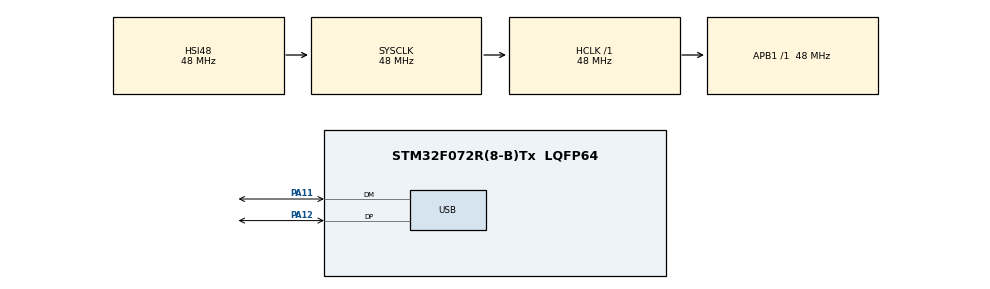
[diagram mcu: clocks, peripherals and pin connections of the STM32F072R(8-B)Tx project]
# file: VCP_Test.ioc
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Mcu.Family=STM32F0
Mcu.Name=STM32F072R(8-B)Tx
Mcu.Package=LQFP64
NVIC.USB_IRQn=true\:0\:0\:false\:false\:true\:false\:true
PA11.Mode=Device
PA11.Signal=USB_DM
PA12.Mode=Device
PA12.Signal=USB_DP
PA13.Mode=Serial_Wire
PA13.Signal=SYS_SWDIO
PA14.Mode=Serial_Wire
PA14.Signal=SYS_SWCLK
ProjectManager.HeapSize=0x200
ProjectManager.StackSize=0x400
ProjectManager.TargetToolchain=MDK-ARM V5
RCC.AHBFreq_Value=48000000
RCC.APB1Freq_Value=48000000
RCC.APB1TimFreq_Value=48000000
RCC.HCLKFreq_Value=48000000
RCC.SYSCLKFreq_VALUE=48000000
RCC.SYSCLKSource=RCC_SYSCLKSOURCE_HSI48
USB_DEVICE.CLASS_NAME_FS=CDC
USB_DEVICE.VirtualMode=Cdc
USB_DEVICE.VirtualModeFS=Cdc_FS
VP_USB_DEVICE_VS_USB_DEVICE_CDC_FS.Mode=CDC_FS
board=custom

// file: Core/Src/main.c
/* USER CODE BEGIN Header */
/**
  ******************************************************************************
  * @file           : main.c
  * @brief          : Main program body
  ******************************************************************************
  * @attention
  *
  * <h2><center>&copy; Copyright (c) 2020 STMicroelectronics.
  * All rights reserved.</center></h2>
  *
  * This software component is licensed by ST under Ultimate Liberty license
  * SLA0044, the "License"; You may not use this file except in compliance with
  * the License. You may obtain a copy of the License at:
  *                             www.st.com/SLA0044
  *
  ******************************************************************************
  */
/* USER CODE END Header */

#include "main.h"
#include "usb_device.h"
#include "gpio.h"

/* USER CODE BEGIN Includes */
#include "usbd_cdc_if.h"

/* USER CODE END Includes */

void SystemClock_Config(void);

int main(void)
{

  /* MCU Configuration--------------------------------------------------------*/

  /* Reset of all peripherals, Initializes the Flash interface and the Systick. */
  HAL_Init();

  /* Configure the system clock */
  SystemClock_Config();

  /* Initialize all configured peripherals */
  MX_GPIO_Init();
  MX_USB_DEVICE_Init();

  /* Infinite loop */
  while (1)
  {

    /* USER CODE BEGIN 3 */
		Main_loop();
  }
  /* USER CODE END 3 */
}

void SystemClock_Config(void)
{
  RCC_OscInitTypeDef RCC_OscInitStruct = {0};
  RCC_ClkInitTypeDef RCC_ClkInitStruct = {0};
  RCC_PeriphCLKInitTypeDef PeriphClkInit = {0};

  /** Initializes the CPU, AHB and APB busses clocks
  */
  RCC_OscInitStruct.OscillatorType = RCC_OSCILLATORTYPE_HSI48;
  RCC_OscInitStruct.HSI48State = RCC_HSI48_ON;
  RCC_OscInitStruct.PLL.PLLState = RCC_PLL_NONE;
  if (HAL_RCC_OscConfig(&RCC_OscInitStruct) != HAL_OK)
  {
    Error_Handler();
  }
  /** Initializes the CPU, AHB and APB busses clocks
  */
  RCC_ClkInitStruct.ClockType = RCC_CLOCKTYPE_HCLK|RCC_CLOCKTYPE_SYSCLK
                              |RCC_CLOCKTYPE_PCLK1;
  RCC_ClkInitStruct.SYSCLKSource = RCC_SYSCLKSOURCE_HSI48;
  RCC_ClkInitStruct.AHBCLKDivider = RCC_SYSCLK_DIV1;
  RCC_ClkInitStruct.APB1CLKDivider = RCC_HCLK_DIV1;

  if (HAL_RCC_ClockConfig(&RCC_ClkInitStruct, FLASH_LATENCY_1) != HAL_OK)
  {
    Error_Handler();
  }
  PeriphClkInit.PeriphClockSelection = RCC_PERIPHCLK_USB;
  PeriphClkInit.UsbClockSelection = RCC_USBCLKSOURCE_HSI48;

  if (HAL_RCCEx_PeriphCLKConfig(&PeriphClkInit) != HAL_OK)
  {
    Error_Handler();
  }
}

void Error_Handler(void)
{
}

/************************ (C) COPYRIGHT STMicroelectronics *****END OF FILE****/
